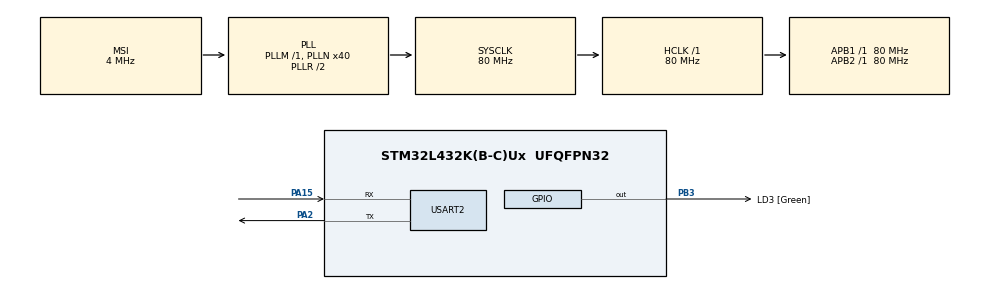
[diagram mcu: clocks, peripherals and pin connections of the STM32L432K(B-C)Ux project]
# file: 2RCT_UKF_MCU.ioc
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Mcu.Family=STM32L4
Mcu.Name=STM32L432K(B-C)Ux
Mcu.Package=UFQFPN32
NVIC.PriorityGroup=NVIC_PRIORITYGROUP_4
NVIC.USART2_IRQn=true\:0\:0\:false\:false\:true\:true\:true\:true
PA15\ (JTDI).Mode=Asynchronous
PA15\ (JTDI).Signal=USART2_RX
PA2.Mode=Asynchronous
PA2.Signal=USART2_TX
PB3\ (JTDO-TRACESWO).GPIO_Label=LD3 [Green]
PB3\ (JTDO-TRACESWO).Signal=GPIO_Output
PC14-OSC32_IN\ (PC14).Signal=RCC_OSC32_IN
PC15-OSC32_OUT\ (PC15).Signal=RCC_OSC32_OUT
ProjectManager.HeapSize=0x200
ProjectManager.StackSize=0x400
ProjectManager.TargetToolchain=STM32CubeIDE
RCC.AHBFreq_Value=80000000
RCC.APB1Freq_Value=80000000
RCC.APB1TimFreq_Value=80000000
RCC.APB2Freq_Value=80000000
RCC.APB2TimFreq_Value=80000000
RCC.CortexFreq_Value=80000000
RCC.HCLKFreq_Value=80000000
RCC.HSE_VALUE=8000000
RCC.HSI16_VALUE=16000000
RCC.HSI48_VALUE=48000000
RCC.HSI_VALUE=16000000
RCC.LSE_VALUE=32768
RCC.MSI_VALUE=4000000
RCC.PLLMUL=RCC_PLLMUL_4
RCC.PLLN=40
RCC.SYSCLKFreq_VALUE=80000000
RCC.SYSCLKSource=RCC_SYSCLKSOURCE_PLLCLK
RCC.VCOOutputFreq_Value=160000000
USART2.VirtualMode-Asynchronous=VM_ASYNC
board=NUCLEO-L432KC

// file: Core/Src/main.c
/* USER CODE BEGIN Header */
/**
 ******************************************************************************
 * @file           : main.c
 * @brief          : Main program body
 ******************************************************************************
 * @attention
 *
 * Copyright (c) 2023 STMicroelectronics.
 * All rights reserved.
 *
 * This software is licensed under terms that can be found in the LICENSE file
 * in the root directory of this software component.
 * If no LICENSE file comes with this software, it is provided AS-IS.
 *
 ******************************************************************************
 */
/* USER CODE END Header */
#include "main.h"

/* USER CODE BEGIN Includes */
#include "SoC_Estimation_UKF_2RC_for_MCU.h"
#include <stdlib.h>
#include <string.h>
#include <stdio.h>
/* USER CODE END Includes */

UART_HandleTypeDef huart2;

/* USER CODE BEGIN PV */
uint8_t rx_buffer[1]; //UART input byte
char input_data[50]; // String build byte by byte
char output_data[50]; // UART output string
char *token; // Variable for string split
uint32_t start_time = 0;
uint32_t elapsed_time = 0;
uint8_t process_data = 0; //Flag to start processing data
uint32_t beat = 0;
/* USER CODE END PV */

void SystemClock_Config(void);
static void MX_GPIO_Init(void);
static void MX_USART2_UART_Init(void);

int main(void)
{
  /* USER CODE BEGIN 1 */
  beat = HAL_GetTick();
  /* USER CODE END 1 */

  /* MCU Configuration--------------------------------------------------------*/

  /* Reset of all peripherals, Initializes the Flash interface and the Systick. */
  HAL_Init();

  /* USER CODE BEGIN Init */
  SoC_Estimation_UKF_2RC_for_MCU_initialize();
  /* USER CODE END Init */

  /* Configure the system clock */
  SystemClock_Config();

  /* Initialize all configured peripherals */
  MX_GPIO_Init();
  MX_USART2_UART_Init();
  /* USER CODE BEGIN 2 */
	HAL_UART_Receive_IT(&huart2, rx_buffer, 1);
  /* USER CODE END 2 */

  /* Infinite loop */
  /* USER CODE BEGIN WHILE */
	while (1) {
		Heartbeat();
		if (process_data == 1) {
					// UART input data is ready to be processed
					start_time = HAL_GetTick();
					token = strtok(input_data, ";");
					rtU.current = atof(token);
					while (token != NULL) {
						token = strtok(NULL, " ");
						if (token != NULL) {
							rtU.voltage = atof(token);
						}
					}
					SoC_Estimation_UKF_2RC_for_MCU_step();
					elapsed_time = HAL_GetTick() - start_time;
					sprintf(output_data, "%ld;%.4f;%.4f;%.4f\r", elapsed_time, rtY.SoCEstimatedUKF, rtY.voltageEstimatedUKF, rtY.SoCMeasuredUKF);
					process_data = 0; //The input data has been processed
					HAL_UART_Transmit_IT(&huart2, (uint8_t*) output_data, sizeof(output_data));
					memset(input_data, 0, strlen(input_data)); //clean input data
				}

    /* USER CODE END WHILE */

	}
}

void SystemClock_Config(void)
{
  RCC_OscInitTypeDef RCC_OscInitStruct = {0};
  RCC_ClkInitTypeDef RCC_ClkInitStruct = {0};

  /** Configure the main internal regulator output voltage
  */
  if (HAL_PWREx_ControlVoltageScaling(PWR_REGULATOR_VOLTAGE_SCALE1) != HAL_OK)
  {
    Error_Handler();
  }

  /** Initializes the RCC Oscillators according to the specified parameters
  * in the RCC_OscInitTypeDef structure.
  */
  RCC_OscInitStruct.OscillatorType = RCC_OSCILLATORTYPE_MSI;
  RCC_OscInitStruct.MSIState = RCC_MSI_ON;
  RCC_OscInitStruct.MSICalibrationValue = 0;
  RCC_OscInitStruct.MSIClockRange = RCC_MSIRANGE_6;
  RCC_OscInitStruct.PLL.PLLState = RCC_PLL_ON;
  RCC_OscInitStruct.PLL.PLLSource = RCC_PLLSOURCE_MSI;
  RCC_OscInitStruct.PLL.PLLM = 1;
  RCC_OscInitStruct.PLL.PLLN = 40;
  RCC_OscInitStruct.PLL.PLLP = RCC_PLLP_DIV7;
  RCC_OscInitStruct.PLL.PLLQ = RCC_PLLQ_DIV2;
  RCC_OscInitStruct.PLL.PLLR = RCC_PLLR_DIV2;
  if (HAL_RCC_OscConfig(&RCC_OscInitStruct) != HAL_OK)
  {
    Error_Handler();
  }

  /** Initializes the CPU, AHB and APB buses clocks
  */
  RCC_ClkInitStruct.ClockType = RCC_CLOCKTYPE_HCLK|RCC_CLOCKTYPE_SYSCLK
                              |RCC_CLOCKTYPE_PCLK1|RCC_CLOCKTYPE_PCLK2;
  RCC_ClkInitStruct.SYSCLKSource = RCC_SYSCLKSOURCE_PLLCLK;
  RCC_ClkInitStruct.AHBCLKDivider = RCC_SYSCLK_DIV1;
  RCC_ClkInitStruct.APB1CLKDivider = RCC_HCLK_DIV1;
  RCC_ClkInitStruct.APB2CLKDivider = RCC_HCLK_DIV1;

  if (HAL_RCC_ClockConfig(&RCC_ClkInitStruct, FLASH_LATENCY_4) != HAL_OK)
  {
    Error_Handler();
  }
}

static void MX_USART2_UART_Init(void)
{

  huart2.Instance = USART2;
  huart2.Init.BaudRate = 115200;
  huart2.Init.WordLength = UART_WORDLENGTH_8B;
  huart2.Init.StopBits = UART_STOPBITS_1;
  huart2.Init.Parity = UART_PARITY_NONE;
  huart2.Init.Mode = UART_MODE_TX_RX;
  huart2.Init.HwFlowCtl = UART_HWCONTROL_NONE;
  huart2.Init.OverSampling = UART_OVERSAMPLING_16;
  huart2.Init.OneBitSampling = UART_ONE_BIT_SAMPLE_DISABLE;
  huart2.AdvancedInit.AdvFeatureInit = UART_ADVFEATURE_NO_INIT;
  if (HAL_UART_Init(&huart2) != HAL_OK)
  {
    Error_Handler();
  }

}

static void MX_GPIO_Init(void)
{
  GPIO_InitTypeDef GPIO_InitStruct = {0};

  /* GPIO Ports Clock Enable */
  __HAL_RCC_GPIOC_CLK_ENABLE();
  __HAL_RCC_GPIOA_CLK_ENABLE();
  __HAL_RCC_GPIOB_CLK_ENABLE();

  /*Configure GPIO pin Output Level */
  HAL_GPIO_WritePin(LD3_GPIO_Port, LD3_Pin, GPIO_PIN_RESET);

  /*Configure GPIO pin : LD3_Pin */
  GPIO_InitStruct.Pin = LD3_Pin;
  GPIO_InitStruct.Mode = GPIO_MODE_OUTPUT_PP;
  GPIO_InitStruct.Pull = GPIO_NOPULL;
  GPIO_InitStruct.Speed = GPIO_SPEED_FREQ_LOW;
  HAL_GPIO_Init(LD3_GPIO_Port, &GPIO_InitStruct);

}

/* USER CODE BEGIN 4 */
void HAL_UART_RxCpltCallback(UART_HandleTypeDef *huart) {
	if (rx_buffer[0] != '\r') {
		// Read the byte/char and add it to the data variable if there is no \r
		strcat(input_data, (char*) rx_buffer);
		HAL_UART_Receive_IT(&huart2, rx_buffer, 1); //we are still waiting for more data, we will continuo reading
	} else {
		//We get the line terminator, then process the data and send
		process_data = 1;
	}
}

void HAL_UART_TxCpltCallback(UART_HandleTypeDef *huart) {
	process_data = 0; // the input data has been processed and send
	HAL_UART_Receive_IT(&huart2, rx_buffer, 1);
}

void Heartbeat(){
	if (HAL_GetTick() - beat > 500){
		HAL_GPIO_TogglePin(GPIOB, GPIO_PIN_3);
		beat = HAL_GetTick();
	}
}
/* USER CODE END 4 */

void Error_Handler(void)
{
	__disable_irq();
	while (1) {
	}
}
